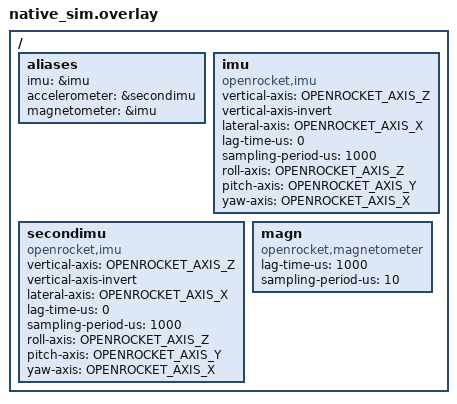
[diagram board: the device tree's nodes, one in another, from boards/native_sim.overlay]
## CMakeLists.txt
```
cmake_minimum_required(VERSION 3.20.0)

set(FSW_ROOT ${CMAKE_CURRENT_SOURCE_DIR}/../../..)

find_package(Zephyr REQUIRED HINTS $ENV{ZEPHYR_BASE})
project(madgwick LANGUAGES CXX)

target_compile_options(app PRIVATE -Wall -Wextra -Wno-unused-parameter -Wno-unused-function -Wno-ignored-qualifiers)
FILE(GLOB app_sources src/*.cpp)
target_sources(app PRIVATE ${app_sources})
```

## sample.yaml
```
sample:
  description:
  name: madgwick
common:
  build_only: true
  platform_allow:
    - native_sim
tests:
  samples.madgwick.default: {}
```

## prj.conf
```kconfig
CONFIG_CPP=y
CONFIG_REQUIRES_FULL_LIBCPP=y
CONFIG_STD_CPP20=y

CONFIG_SENSOR=y

CONFIG_F_CORE=y
CONFIG_F_CORE_SENSOR=y
CONFIG_F_CORE_MATH=y
CONFIG_F_CORE_OS=y

 # outputs
CONFIG_SERIAL=y
CONFIG_FILE_SYSTEM_SHELL=y
CONFIG_HEAP_MEM_POOL_SIZE=8192

CONFIG_DEBUG=y
CONFIG_CBPRINTF_FP_SUPPORT=y

CONFIG_ZSL=y
CONFIG_MAIN_STACK_SIZE=4096
```

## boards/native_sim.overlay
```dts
/ {
	aliases {
		imu = &imu;
		accelerometer = &secondimu;
		magnetometer = &imu;
	};

    imu: imu {
        status = "okay";
        compatible = "openrocket,imu";
        vertical-axis = "OPENROCKET_AXIS_Z";
        vertical-axis-invert;
        lateral-axis = "OPENROCKET_AXIS_X";
        lag-time-us = <0>;
        sampling-period-us = <1000>;

        roll-axis = "OPENROCKET_AXIS_Z";
        pitch-axis = "OPENROCKET_AXIS_Y";
        yaw-axis = "OPENROCKET_AXIS_X";
    };


    secondimu: secondimu {
        status = "okay";
        compatible = "openrocket,imu";
        vertical-axis = "OPENROCKET_AXIS_Z";
        vertical-axis-invert;
        lateral-axis = "OPENROCKET_AXIS_X";
        lag-time-us = <0>;
        sampling-period-us = <1000>;

        roll-axis = "OPENROCKET_AXIS_Z";
        pitch-axis = "OPENROCKET_AXIS_Y";
        yaw-axis = "OPENROCKET_AXIS_X";
    };

    magn: magn {
        status = "okay";
        compatible = "openrocket,magnetometer";
        lag-time-us = <1000>;
		sampling-period-us = <10>;
    };

};
```

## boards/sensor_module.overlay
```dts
/ {
	aliases {
		imu = &lsm6dsl;
		accelerometer = &adxl375;
		magnetometer = &lis3mdl;
	};
};
```

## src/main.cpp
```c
#include <f_core/math/filters/c_madgwick.h>
#include <f_core/device/sensor/c_accelerometer.h>
#include <f_core/device/sensor/c_gyroscope.h>
#include <f_core/device/sensor/c_magnetometer.h>

int main() {
    CMadgwick madgwickFilter(100.0);
    CAccelerometer accelerometer(*DEVICE_DT_GET(DT_ALIAS(imu)));
    CGyroscope gyroscope(*DEVICE_DT_GET(DT_ALIAS(imu)));
    CMagnetometer magnetometer(*DEVICE_DT_GET(DT_ALIAS(magnetometer)));

    zsl_mtx accelInitData[100];
    zsl_mtx gyroInitData[100];
    zsl_mtx magnInitData[100];

    for (int i = 0; i < 100; i++) {
        accelerometer.UpdateSensorValue();
        gyroscope.UpdateSensorValue();
        magnetometer.UpdateSensorValue();

        accelInitData[i].data[0] = accelerometer.GetSensorValueFloat(SENSOR_CHAN_ACCEL_X);
        accelInitData[i].data[1] = accelerometer.GetSensorValueFloat(SENSOR_CHAN_ACCEL_Y);
        accelInitData[i].data[2] = accelerometer.GetSensorValueFloat(SENSOR_CHAN_ACCEL_Z);

        gyroInitData[i].data[0] = gyroscope.GetSensorValueFloat(SENSOR_CHAN_GYRO_X);
        gyroInitData[i].data[1] = gyroscope.GetSensorValueFloat(SENSOR_CHAN_GYRO_Y);
        gyroInitData[i].data[2] = gyroscope.GetSensorValueFloat(SENSOR_CHAN_GYRO_Z);

        magnInitData[i].data[0] = magnetometer.GetSensorValueFloat(SENSOR_CHAN_MAGN_X);
        magnInitData[i].data[1] = magnetometer.GetSensorValueFloat(SENSOR_CHAN_MAGN_Y);
        magnInitData[i].data[2] = magnetometer.GetSensorValueFloat(SENSOR_CHAN_MAGN_Z);

        k_msleep(10);
    }

    int ret = madgwickFilter.CalibrateBetaTerm(accelInitData, gyroInitData, magnInitData, nullptr);
    if (ret < 0) {
        return ret;
    }

    zsl_real_t accelX = 0.0;
    zsl_real_t accelY = 0.0;
    zsl_real_t accelZ = 0.0;

    zsl_real_t gyroX = 0.0;
    zsl_real_t gyroY = 0.0;
    zsl_real_t gyroZ = 0.0;

    zsl_real_t magnX = 0.0;
    zsl_real_t magnY = 0.0;
    zsl_real_t magnZ = 0.0;

    zsl_quat quatOut;

    while (true) {
        accelerometer.UpdateSensorValue();
        gyroscope.UpdateSensorValue();
        magnetometer.UpdateSensorValue();

        accelX = accelerometer.GetSensorValueFloat(SENSOR_CHAN_ACCEL_X);
        accelY = accelerometer.GetSensorValueFloat(SENSOR_CHAN_ACCEL_Y);
        accelZ = accelerometer.GetSensorValueFloat(SENSOR_CHAN_ACCEL_Z);

        gyroX = gyroscope.GetSensorValueFloat(SENSOR_CHAN_GYRO_X);
        gyroY = gyroscope.GetSensorValueFloat(SENSOR_CHAN_GYRO_Y);
        gyroZ = gyroscope.GetSensorValueFloat(SENSOR_CHAN_GYRO_Z);

        magnX = magnetometer.GetSensorValueFloat(SENSOR_CHAN_MAGN_X);
        magnY = magnetometer.GetSensorValueFloat(SENSOR_CHAN_MAGN_Y);
        magnZ = magnetometer.GetSensorValueFloat(SENSOR_CHAN_MAGN_Z);

        madgwickFilter.FeedAccel(accelX, accelY, accelZ);
        madgwickFilter.FeedGyro(gyroX, gyroY, gyroZ);
        madgwickFilter.FeedMagn(magnX, magnY, magnZ);

        madgwickFilter.Update(quatOut);
    }

    return 0;
}
```
